# Z20K14xM register map
Vendor: Zhixin Semiconductor; Series: Z20K14xM; File version: 0.1.0
CPU: CM4 r0p1, little endian, no MPU, FPU, 4 interrupt priority bits
Registers are 32-bit, read-write, reset 0x0 unless marked. A register's access mark holds for its fields unless they carry their own. Offsets are from the block's base; [hi:lo] are bit positions; {n}, {i} and the like mark numbered series; 'fields as' and 'values as' point back to an identical list.

## PARCC
Base 0x40065000
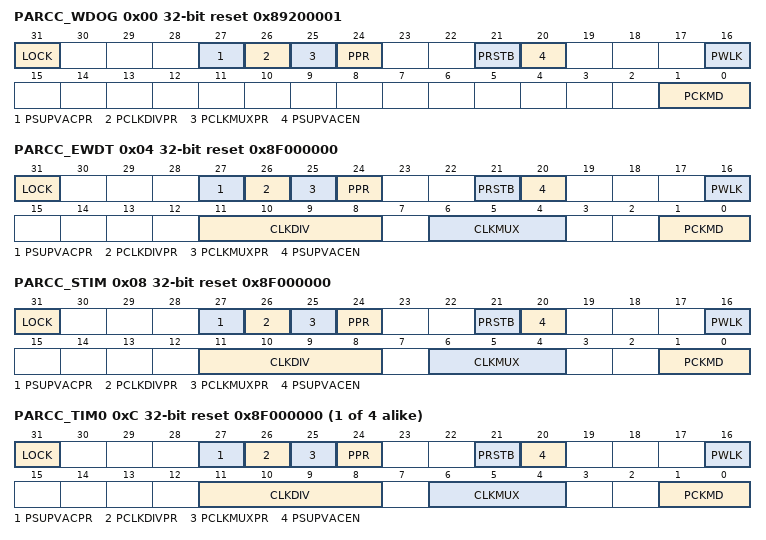
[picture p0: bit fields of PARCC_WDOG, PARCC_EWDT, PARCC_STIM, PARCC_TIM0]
0x00 PARCC_WDOG reset 0x89200001 — PARCC for WDOG (PARCC_WDOG)
  [31] LOCK — Write register lock
  [27] PSUPVACPR — Peripheral supervisor access control present
  [26] PCLKDIVPR — Peripheral clock divider present
  [25] PCLKMUXPR — Peripheral clock mux present
  [24] PPR — Peripheral present
  [21] PRSTB — Peripheral reset_b
  [20] PSUPVACEN — Peripheral supervisor access control enable
  [16] PWLK — Peripheral write lock
  [1:0] PCKMD — Peripheral Clock Mode
0x04 PARCC_EWDT reset 0x8F000000 — PARCC for EWDT (PARCC_EWDT)
  [31] LOCK — Write register lock
  [27] PSUPVACPR — Peripheral supervisor access control present
  [26] PCLKDIVPR — Peripheral clock divider present
  [25] PCLKMUXPR — Peripheral clock mux present
  [24] PPR — Peripheral present
  [21] PRSTB — Peripheral reset_b
  [20] PSUPVACEN — Peripheral supervisor access control enable
  [16] PWLK — Peripheral write lock
  [11:8] CLKDIV — Peripheral funcional clock divider
  [6:4] CLKMUX — Peripheral funcional clock source mux
  [1:0] PCKMD — Peripheral Clock Mode
0x08 PARCC_STIM reset 0x8F000000 — PARCC for STIM (PARCC_STIM)
  fields as PARCC_EWDT
{0xC+4i} PARCC_TIM{i} reset 0x8F000000 (i=0..3) — PARCC for TIM{i} (PARCC_TIM{i})
  fields as PARCC_EWDT
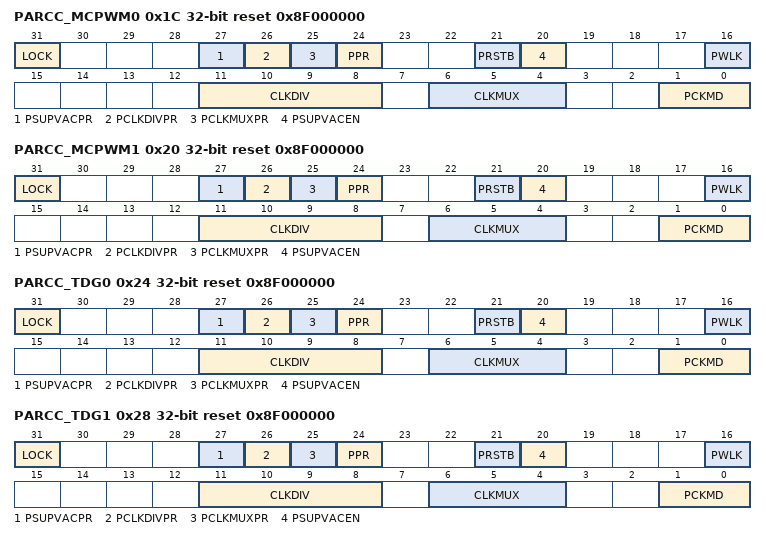
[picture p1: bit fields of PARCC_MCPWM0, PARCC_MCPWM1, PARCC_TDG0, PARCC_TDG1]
0x1C PARCC_MCPWM0 reset 0x8F000000 — PARCC for MCPWM0 (PARCC_MCPWM0)
  fields as PARCC_EWDT
0x20 PARCC_MCPWM1 reset 0x8F000000 — PARCC for MCPWM1 (PARCC_MCPWM1)
  fields as PARCC_EWDT
0x24 PARCC_TDG0 reset 0x8F000000 — PARCC for TDG0 (PARCC_TDG0)
  fields as PARCC_EWDT
0x28 PARCC_TDG1 reset 0x8F000000 — PARCC for TDG1 (PARCC_TDG1)
  fields as PARCC_EWDT
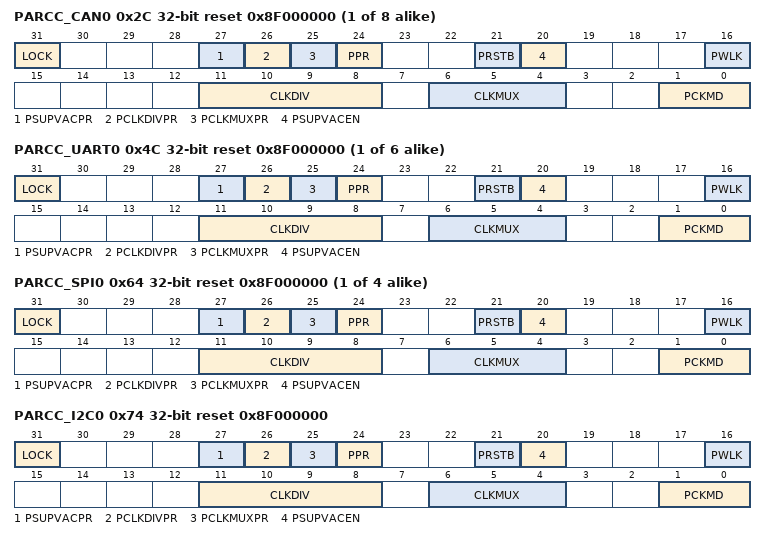
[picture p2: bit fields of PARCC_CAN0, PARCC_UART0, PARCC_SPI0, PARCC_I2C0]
{0x2C+4i} PARCC_CAN{i} reset 0x8F000000 (i=0..7) — PARCC for CAN{i} (PARCC_CAN{i})
  fields as PARCC_EWDT
{0x4C+4i} PARCC_UART{i} reset 0x8F000000 (i=0..5) — PARCC for UART{i} (PARCC_UART{i})
  fields as PARCC_EWDT
{0x64+4i} PARCC_SPI{i} reset 0x8F000000 (i=0..3) — PARCC for SPI{i} (PARCC_SPI{i})
  fields as PARCC_EWDT
0x74 PARCC_I2C0 reset 0x8F000000 — PARCC for I2C0 (PARCC_I2C0)
  fields as PARCC_EWDT
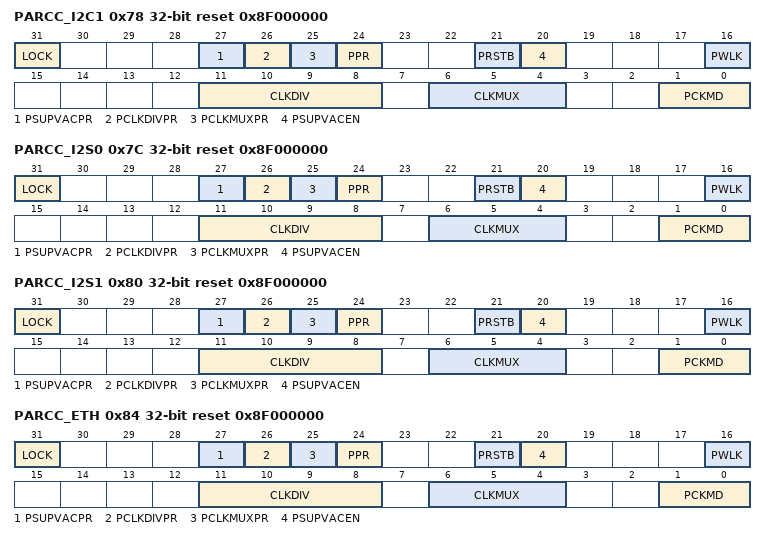
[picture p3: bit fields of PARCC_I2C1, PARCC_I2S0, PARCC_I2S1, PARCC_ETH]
0x78 PARCC_I2C1 reset 0x8F000000 — PARCC for I2C1 (PARCC_I2C1)
  fields as PARCC_EWDT
0x7C PARCC_I2S0 reset 0x8F000000 — PARCC for I2S0 (PARCC_I2S0)
  fields as PARCC_EWDT
0x80 PARCC_I2S1 reset 0x8F000000 — PARCC for I2S1 (PARCC_I2S1)
  fields as PARCC_EWDT
0x84 PARCC_ETH reset 0x8F000000 — PARCC for ETH (PARCC_ETH)
  fields as PARCC_EWDT
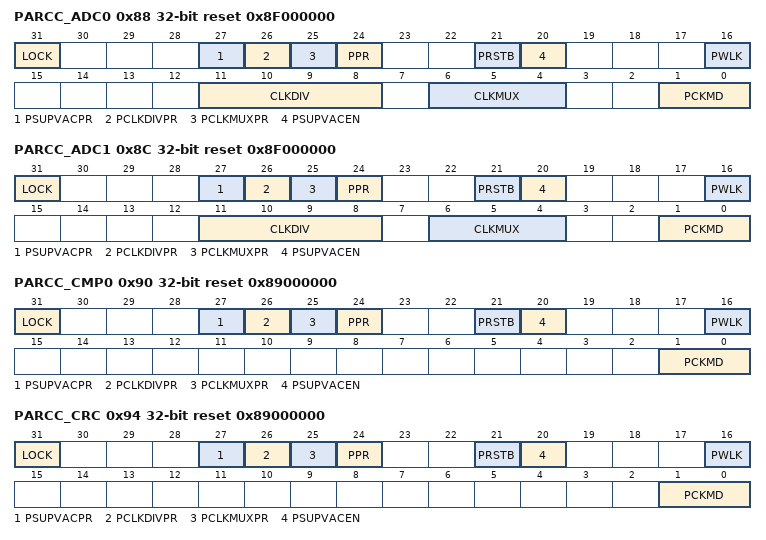
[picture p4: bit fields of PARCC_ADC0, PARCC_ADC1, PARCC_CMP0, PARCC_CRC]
0x88 PARCC_ADC0 reset 0x8F000000 — PARCC for ADC0 (PARCC_ADC0)
  fields as PARCC_EWDT
0x8C PARCC_ADC1 reset 0x8F000000 — PARCC for ADC1 (PARCC_ADC1)
  fields as PARCC_EWDT
0x90 PARCC_CMP0 reset 0x89000000 — PARCC for CMP0 (PARCC_CMP0)
  fields as PARCC_WDOG
0x94 PARCC_CRC reset 0x89000000 — PARCC for CRC (PARCC_CRC)
  fields as PARCC_WDOG
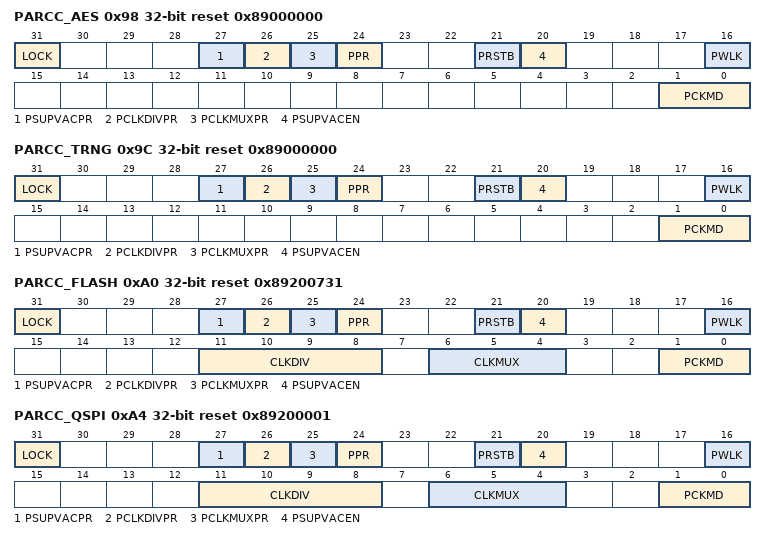
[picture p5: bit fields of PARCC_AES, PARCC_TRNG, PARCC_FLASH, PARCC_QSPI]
0x98 PARCC_AES reset 0x89000000 — PARCC for AES (PARCC_AES)
  fields as PARCC_WDOG
0x9C PARCC_TRNG reset 0x89000000 — PARCC for TRNG (PARCC_TRNG)
  fields as PARCC_WDOG
0xA0 PARCC_FLASH reset 0x89200731 — PARCC for FLASH (PARCC_FLASH)
  fields as PARCC_EWDT
0xA4 PARCC_QSPI reset 0x89200001 — PARCC for QSPI (PARCC_QSPI)
  fields as PARCC_EWDT
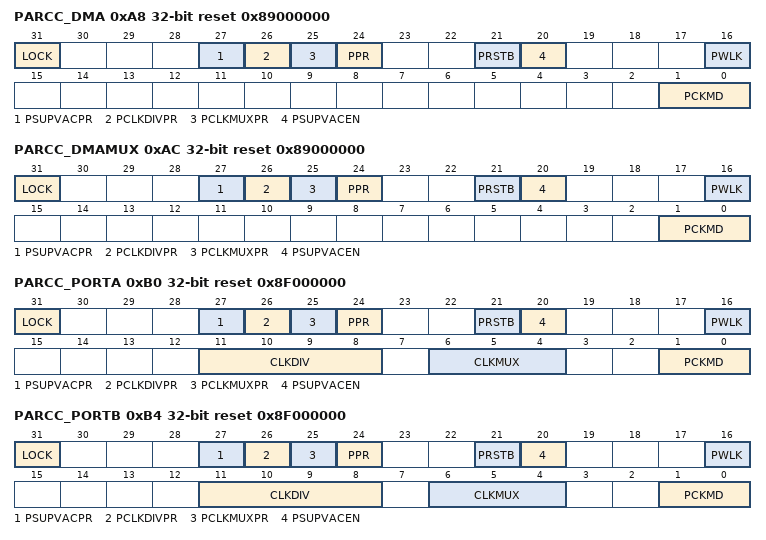
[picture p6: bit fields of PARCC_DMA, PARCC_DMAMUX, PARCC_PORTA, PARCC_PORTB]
0xA8 PARCC_DMA reset 0x89000000 — PARCC for DMA (PARCC_DMA)
  fields as PARCC_WDOG
0xAC PARCC_DMAMUX reset 0x89000000 — PARCC for DMAMUX (PARCC_DMAMUX)
  fields as PARCC_WDOG
0xB0 PARCC_PORTA reset 0x8F000000 — PARCC for PORTA (PARCC_PORTA)
  fields as PARCC_EWDT
0xB4 PARCC_PORTB reset 0x8F000000 — PARCC for PORTB (PARCC_PORTB)
  fields as PARCC_EWDT
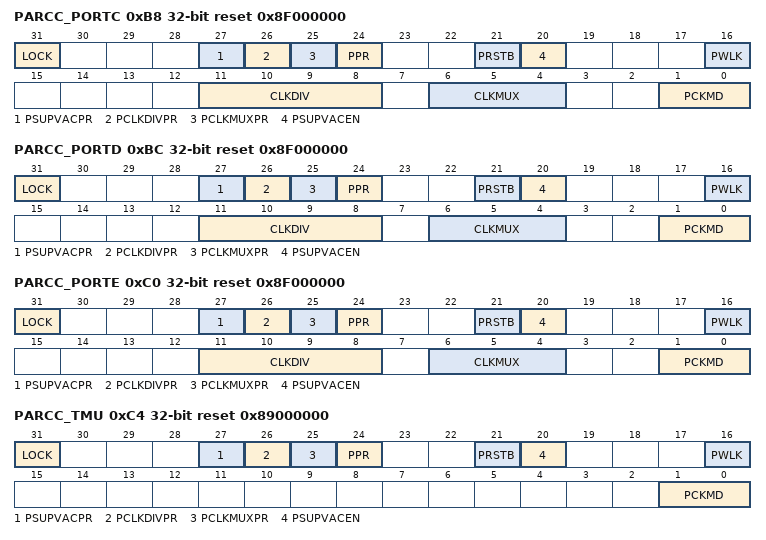
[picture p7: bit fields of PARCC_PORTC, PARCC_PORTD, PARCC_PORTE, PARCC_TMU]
0xB8 PARCC_PORTC reset 0x8F000000 — PARCC for PORTC (PARCC_PORTC)
  fields as PARCC_EWDT
0xBC PARCC_PORTD reset 0x8F000000 — PARCC for PORTD (PARCC_PORTD)
  fields as PARCC_EWDT
0xC0 PARCC_PORTE reset 0x8F000000 — PARCC for PORTE (PARCC_PORTE)
  fields as PARCC_EWDT
0xC4 PARCC_TMU reset 0x89000000 — PARCC for TMU (PARCC_TMU)
  fields as PARCC_WDOG
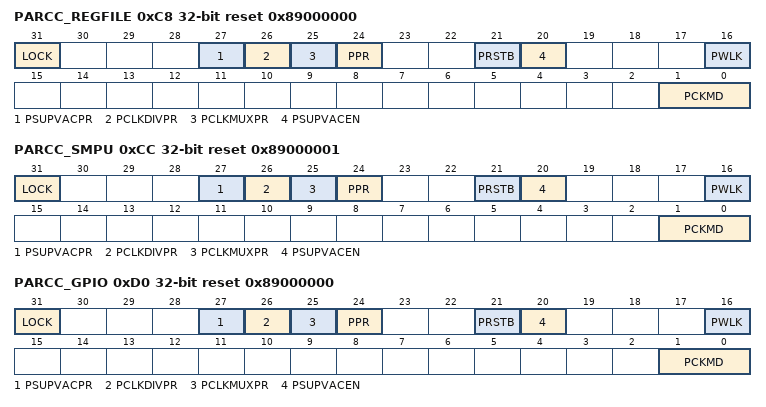
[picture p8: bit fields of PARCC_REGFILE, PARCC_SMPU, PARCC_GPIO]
0xC8 PARCC_REGFILE reset 0x89000000 — PARCC for REGFILE (PARCC_REGFILE)
  fields as PARCC_WDOG
0xCC PARCC_SMPU reset 0x89000001 — PARCC for SMPU (PARCC_SMPU)
  fields as PARCC_WDOG
0xD0 PARCC_GPIO reset 0x89000000 — PARCC for GPIO (PARCC_GPIO)
  fields as PARCC_WDOG
